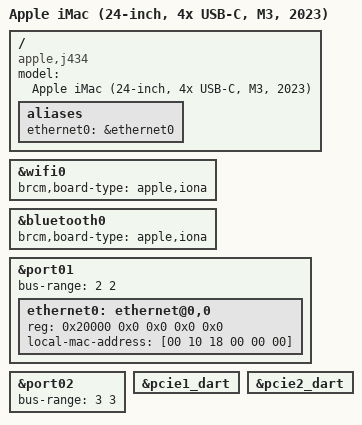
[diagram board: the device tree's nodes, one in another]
// SPDX-License-Identifier: GPL-2.0+ OR MIT
/*
 * Apple iMac (24-inch, 4x USB-C, M3, 2023)
 *
 * target-type: J434
 *
 * Copyright The Asahi Linux Contributors
 */

/dts-v1/;

#include "t8122.dtsi"
#include "t8122-usbpd-i2c.dtsi"
#include "t8122-jxxx.dtsi"

/ {
	compatible = "apple,j434", "apple,t8122", "apple,arm-platform";
	model = "Apple iMac (24-inch, 4x USB-C, M3, 2023)";

	aliases {
		ethernet0 = &ethernet0;
	};
};

&wifi0 {
	brcm,board-type = "apple,iona";
};

&bluetooth0 {
	brcm,board-type = "apple,iona";
};

&port01 {
	bus-range = <2 2>;

	status = "okay";

	ethernet0: ethernet@0,0 {
		reg = <0x20000 0x0 0x0 0x0 0x0>;
		/* To be filled by the loader */
		local-mac-address = [00 10 18 00 00 00];
	};
};

&port02 {
	bus-range = <3 3>;

	status = "okay";
};

&pcie1_dart {
	status = "okay";
};

&pcie2_dart {
	status = "okay";
};
